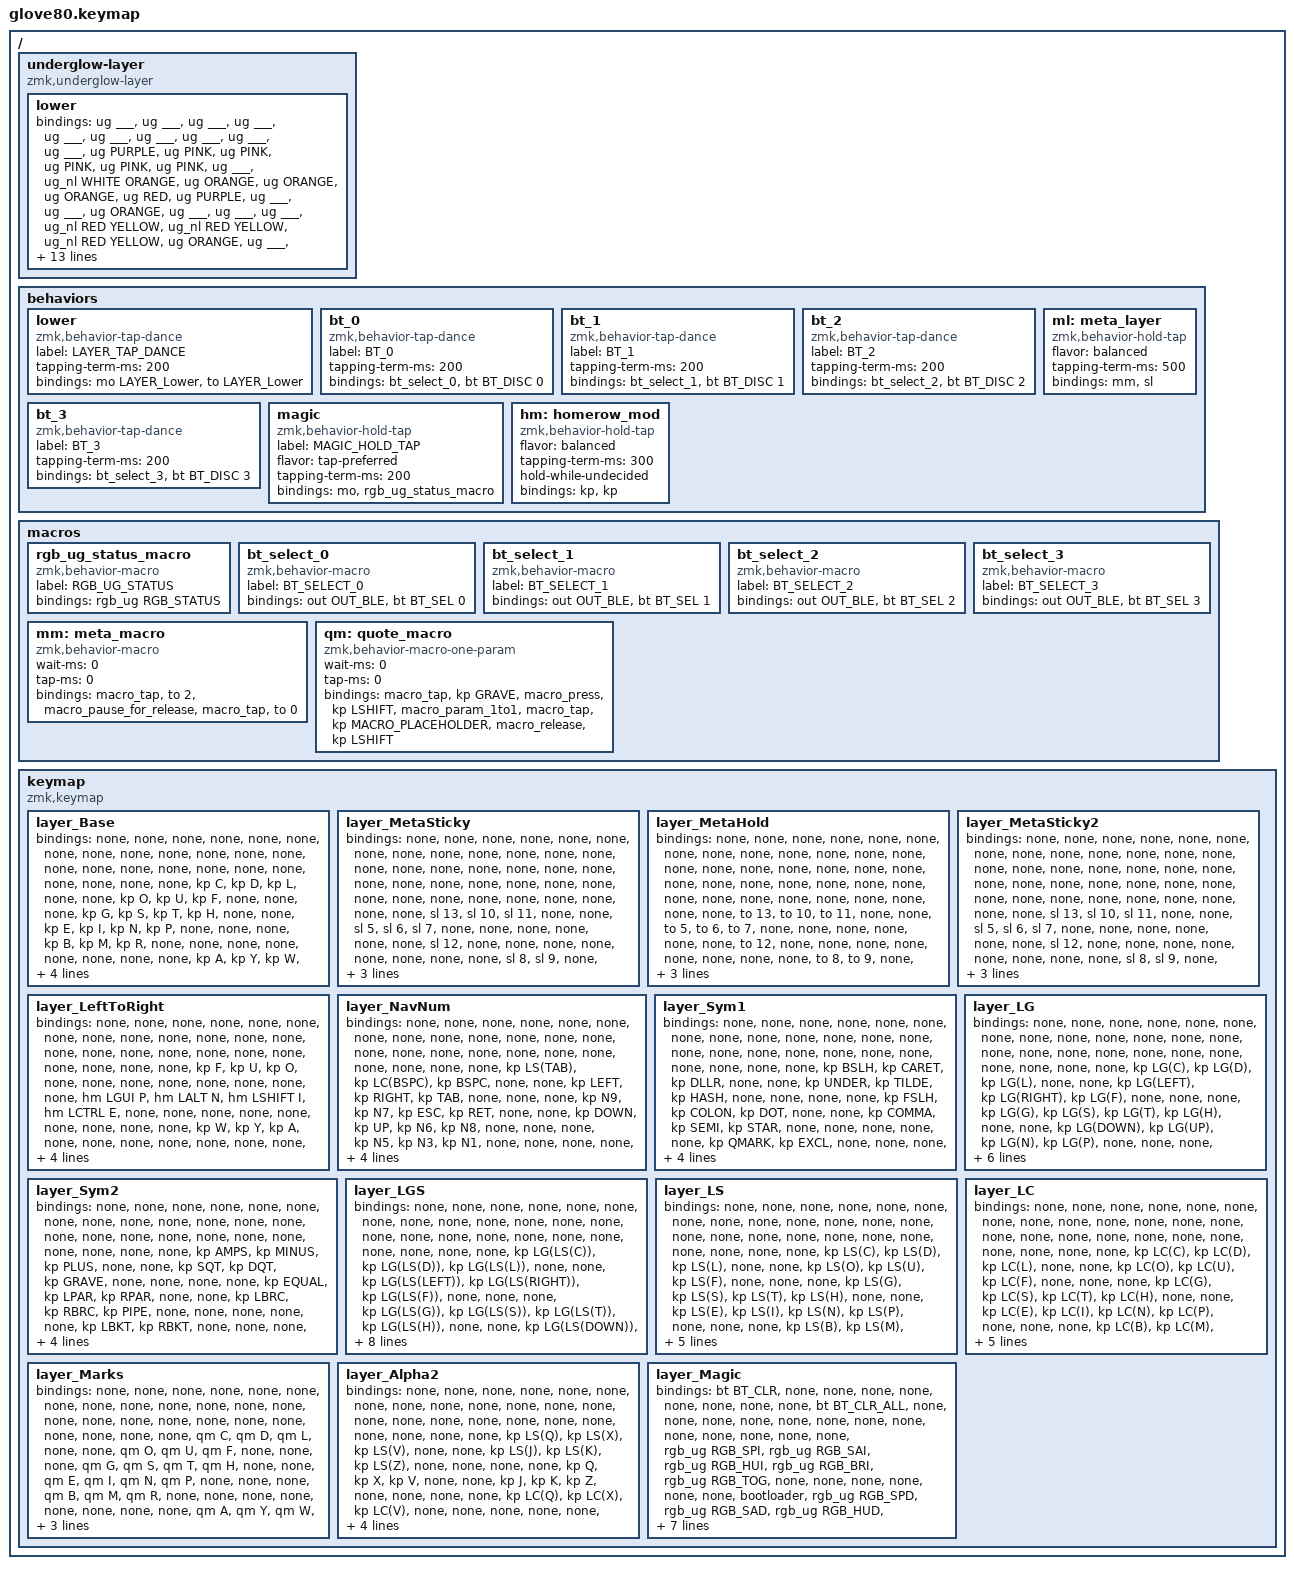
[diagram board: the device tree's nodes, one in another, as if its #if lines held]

/*
 * Copyright (c) 2020 The ZMK Contributors
 * Copyright (c) 2023 Innaworks Development Limited, trading as MoErgo
 *
 * SPDX-License-Identifier: MIT
 */


/* THIS FILE WAS GENERATED BY GLOVE80 LAYOUT EDITOR
 *
 * This file was generated automatically. You may or may not want to
 * edit it directly.
 */

#include <behaviors.dtsi>
/* Include all behavior includes needed */
#include <dt-bindings/zmk/outputs.h>
#include <dt-bindings/zmk/keys.h>
#include <dt-bindings/zmk/bt.h>
#include <dt-bindings/zmk/rgb.h>

/* Automatically generated layer name #define */
#define LAYER_Base 0
#define LAYER_MetaSticky 1
#define LAYER_MetaHold 2
#define LAYER_MetaSticky2 3
#define LAYER_LeftToRight 4
#define LAYER_NavNum 5
#define LAYER_Sym1 6
#define LAYER_Sym2 7
#define LAYER_LG 8
#define LAYER_LGS 9
#define LAYER_LS 10
#define LAYER_LC 11
#define LAYER_Marks 12
#define LAYER_Alpha2 13
#define LAYER_Magic 14

/* To deal with the situation where there is no Lower layer, to keep &lower happy */
#ifndef LAYER_Lower
#define LAYER_Lower 0
#endif

/* Custom Device-tree */
#define GREEN 0x00ff00
#define RED 0xff0000
#define BLUE 0x0000ff
#define TEAL 0x008080
#define ORANGE 0xffa500
#define YELLOW 0xffff00
#define GOLD 0xffd700
#define PURPLE 0x800080
#define PINK 0xffc0cb
#define WHITE 0xffffff
#define ___ 0x000000
/ {
    underglow-layer {
        compatible  = "zmk,underglow-layer";

        lower {
            bindings = <
    &ug ___    &ug ___  &ug ___    &ug ___    &ug ___                                                                                 &ug ___             &ug ___           &ug ___           &ug ___     &ug ___
    &ug PURPLE &ug PINK &ug PINK   &ug   PINK &ug   PINK &ug PINK                                                             &ug ___ &ug_nl WHITE ORANGE &ug ORANGE        &ug ORANGE        &ug ORANGE  &ug RED
    &ug PURPLE &ug ___  &ug ___    &ug ORANGE &ug ___    &ug ___                                                              &ug ___ &ug_nl RED YELLOW   &ug_nl RED YELLOW &ug_nl RED YELLOW &ug ORANGE  &ug ___
    &ug PURPLE &ug ___  &ug ORANGE &ug    RED &ug ORANGE &ug ___                                                              &ug ___ &ug_nl RED YELLOW   &ug_nl RED YELLOW &ug_nl RED YELLOW &ug ORANGE  &ug ___
    &ug   BLUE &ug ___  &ug RED    &ug    RED &ug    RED &ug ___  &ug_cl BLUE TEAL &ug ___   &ug ___  &ug ___ &ug ___ &ug ___ &ug ___ &ug_nl RED YELLOW   &ug_nl RED YELLOW &ug_nl RED YELLOW &ug    RED  &ug BLUE
    &ug ___    &ug ___  &ug ORANGE &ug ORANGE &ug ORANGE          &ug ___          &ug GREEN &ug ___  &ug ___ &ug ___ &ug ___         &ug_nl RED YELLOW   &ug_nl RED YELLOW &ug ORANGE        &ug    RED  &ug ___
                >;
            layer-id = <LAYER_Base>;
        };
    };
};


/* Glove80 system behavior & macros */
/ {
    behaviors {
        // For the "layer" key, it'd nice to be able to use it as either a shift or a toggle.
        // Configure it as a tap dance, so the first tap (or hold) is a &mo and the second tap is a &to
        lower: lower {
            compatible = "zmk,behavior-tap-dance";
            label = "LAYER_TAP_DANCE";
            #binding-cells = <0>;
            tapping-term-ms = <200>;
            bindings = <&mo LAYER_Lower>, <&to LAYER_Lower>;
        };
    };
};

/ {
    macros {
        rgb_ug_status_macro: rgb_ug_status_macro {
            label = "RGB_UG_STATUS";
            compatible = "zmk,behavior-macro";
            #binding-cells = <0>;
            bindings
                = <&rgb_ug RGB_STATUS>;
        };
    };
};


/ {
#ifdef BT_DISC_CMD
    behaviors {
        bt_0: bt_0 {
            compatible = "zmk,behavior-tap-dance";
            label = "BT_0";
            #binding-cells = <0>;
            tapping-term-ms = <200>;
            bindings = <&bt_select_0>, <&bt BT_DISC 0>;
        };
        bt_1: bt_1 {
            compatible = "zmk,behavior-tap-dance";
            label = "BT_1";
            #binding-cells = <0>;
            tapping-term-ms = <200>;
            bindings = <&bt_select_1>, <&bt BT_DISC 1>;
        };
        bt_2: bt_2 {
            compatible = "zmk,behavior-tap-dance";
            label = "BT_2";
            #binding-cells = <0>;
            tapping-term-ms = <200>;
            bindings = <&bt_select_2>, <&bt BT_DISC 2>;
        };
        bt_3: bt_3 {
            compatible = "zmk,behavior-tap-dance";
            label = "BT_3";
            #binding-cells = <0>;
            tapping-term-ms = <200>;
            bindings = <&bt_select_3>, <&bt BT_DISC 3>;
        };
    };
    macros {
        bt_select_0: bt_select_0 {
            label = "BT_SELECT_0";
            compatible = "zmk,behavior-macro";
            #binding-cells = <0>;
            bindings
                = <&out OUT_BLE>,
                  <&bt BT_SEL 0>;
        };
        bt_select_1: bt_select_1 {
            label = "BT_SELECT_1";
            compatible = "zmk,behavior-macro";
            #binding-cells = <0>;
            bindings
                = <&out OUT_BLE>,
                  <&bt BT_SEL 1>;
        };
        bt_select_2: bt_select_2 {
            label = "BT_SELECT_2";
            compatible = "zmk,behavior-macro";
            #binding-cells = <0>;
            bindings
                = <&out OUT_BLE>,
                  <&bt BT_SEL 2>;
        };
        bt_select_3: bt_select_3 {
            label = "BT_SELECT_3";
            compatible = "zmk,behavior-macro";
            #binding-cells = <0>;
            bindings
                = <&out OUT_BLE>,
                  <&bt BT_SEL 3>;
        };
    };
#else
    macros {
        bt_0: bt_0 {
            label = "BT_0";
            compatible = "zmk,behavior-macro";
            #binding-cells = <0>;
            bindings
                = <&out OUT_BLE>,
                  <&bt BT_SEL 0>;
        };
        bt_1: bt_1 {
            label = "BT_1";
            compatible = "zmk,behavior-macro";
            #binding-cells = <0>;
            bindings
                = <&out OUT_BLE>,
                  <&bt BT_SEL 1>;
        };
        bt_2: bt_2 {
            label = "BT_2";
            compatible = "zmk,behavior-macro";
            #binding-cells = <0>;
            bindings
                = <&out OUT_BLE>,
                  <&bt BT_SEL 2>;
        };
        bt_3: bt_3 {
            label = "BT_3";
            compatible = "zmk,behavior-macro";
            #binding-cells = <0>;
            bindings
                = <&out OUT_BLE>,
                  <&bt BT_SEL 3>;
        };
    };
#endif
};

/ {
    behaviors {
        magic: magic {
            compatible = "zmk,behavior-hold-tap";
            label = "MAGIC_HOLD_TAP";
            #binding-cells = <2>;
            flavor = "tap-preferred";
            tapping-term-ms = <200>;
            bindings = <&mo>, <&rgb_ug_status_macro>;
        };
    };
};

/* #define for key positions */
#define POS_LH_T1 52
#define POS_LH_T2 53
#define POS_LH_T3 54
#define POS_LH_T4 69
#define POS_LH_T5 70
#define POS_LH_T6 71
#define POS_LH_C1R2 15
#define POS_LH_C1R3 27
#define POS_LH_C1R4 39
#define POS_LH_C1R5 51
#define POS_LH_C2R1 4
#define POS_LH_C2R2 14
#define POS_LH_C2R3 26
#define POS_LH_C2R4 38
#define POS_LH_C2R5 50
#define POS_LH_C2R6 68
#define POS_LH_C3R1 3
#define POS_LH_C3R2 13
#define POS_LH_C3R3 25
#define POS_LH_C3R4 37
#define POS_LH_C3R5 49
#define POS_LH_C3R6 67
#define POS_LH_C4R1 2
#define POS_LH_C4R2 12
#define POS_LH_C4R3 24
#define POS_LH_C4R4 36
#define POS_LH_C4R5 48
#define POS_LH_C4R6 66
#define POS_LH_C5R1 1
#define POS_LH_C5R2 11
#define POS_LH_C5R3 23
#define POS_LH_C5R4 35
#define POS_LH_C5R5 47
#define POS_LH_C5R6 65
#define POS_LH_C6R1 0
#define POS_LH_C6R2 10
#define POS_LH_C6R3 22
#define POS_LH_C6R4 34
#define POS_LH_C6R5 46
#define POS_LH_C6R6 64
#define POS_RH_T1 57
#define POS_RH_T2 56
#define POS_RH_T3 55
#define POS_RH_T4 74
#define POS_RH_T5 73
#define POS_RH_T6 72
#define POS_RH_C1R2 16
#define POS_RH_C1R3 28
#define POS_RH_C1R4 40
#define POS_RH_C1R5 58
#define POS_RH_C2R1 5
#define POS_RH_C2R2 17
#define POS_RH_C2R3 29
#define POS_RH_C2R4 41
#define POS_RH_C2R5 59
#define POS_RH_C2R6 75
#define POS_RH_C3R1 6
#define POS_RH_C3R2 18
#define POS_RH_C3R3 30
#define POS_RH_C3R4 42
#define POS_RH_C3R5 60
#define POS_RH_C3R6 76
#define POS_RH_C4R1 7
#define POS_RH_C4R2 19
#define POS_RH_C4R3 31
#define POS_RH_C4R4 43
#define POS_RH_C4R5 61
#define POS_RH_C4R6 77
#define POS_RH_C5R1 8
#define POS_RH_C5R2 20
#define POS_RH_C5R3 32
#define POS_RH_C5R4 44
#define POS_RH_C5R5 62
#define POS_RH_C5R6 78
#define POS_RH_C6R1 9
#define POS_RH_C6R2 21
#define POS_RH_C6R3 33
#define POS_RH_C6R4 45
#define POS_RH_C6R5 63
#define POS_RH_C6R6 79

/* Custom Defined Behaviors */
/ {
    behaviors {
        ml: meta_layer {
            compatible = "zmk,behavior-hold-tap";
            flavor = "balanced";
            tapping-term-ms = <500>;
            #binding-cells = <2>;
            bindings = <&mm>, <&sl>;
        };
        hm: homerow_mod {
            compatible = "zmk,behavior-hold-tap";
            flavor = "balanced";
            tapping-term-ms = <300>;
            hold-while-undecided;
            #binding-cells = <2>;
            bindings = <&kp>, <&kp>;
        };
    };

    macros {
        mm: meta_macro {
            compatible = "zmk,behavior-macro";
            wait-ms = <0>;
            tap-ms = <0>;
            #binding-cells = <0>;
            bindings
                = <&macro_tap &to 2>
                , <&macro_pause_for_release>
                , <&macro_tap &to 0>
                ;
        };

        qm: quote_macro {
            compatible = "zmk,behavior-macro-one-param";
            wait-ms = <0>;
            tap-ms = <0>;
            #binding-cells = <1>;
            bindings
                = <&macro_tap &kp GRAVE>
                , <&macro_press &kp LSHIFT>
                , <&macro_param_1to1>
                , <&macro_tap &kp MACRO_PLACEHOLDER>
                , <&macro_release &kp LSHIFT>
                ;
        };
    };

};

/* Automatically generated macro definitions */
/ {
    macros {

    };
};

/* Automatically generated behavior definitions */
/ {
    behaviors {
    
    };
};

/* Automatically generated combos definitions */


/* Automatically generated keymap */
/ {
    keymap {
        compatible = "zmk,keymap";


        layer_Base {
            bindings = <
                &none   &none   &none   &none   &none                                                                       &none   &none   &none   &none                 &none
                &none   &none   &none   &none   &none   &none                                                       &none   &none   &none   &none   &none                 &none
                &none   &none   &kp C   &kp D   &kp L   &none                                                       &none   &kp O   &kp U   &kp F   &none                 &none
                &none   &kp G   &kp S   &kp T   &kp H   &none                                                       &none   &kp E   &kp I   &kp N   &kp P                 &none
                &none   &none   &kp B   &kp M   &kp R   &none      &none   &none   &none   &none   &none    &none   &none   &kp A   &kp Y   &kp W   &none                 &none
 &magic LAYER_Magic 0   &none   &none   &none   &none          &kp SPACE   &sl 4   &none   &none   &none  &ml 1 1           &none   &none   &none   &none  &magic LAYER_Magic 0
            >;
        };

        layer_MetaSticky {
            bindings = <
  &none   &none   &none   &none   &none                                                                   &none   &none   &none   &none   &none
  &none   &none   &none   &none   &none   &none                                                   &none   &none   &none   &none   &none   &none
  &none   &none   &none   &none   &none   &none                                                   &none   &none   &none   &none   &none   &none
  &none   &none  &sl 13  &sl 10  &sl 11   &none                                                   &none   &sl 5   &sl 6   &sl 7   &none   &none
  &none   &none   &none   &none  &sl 12   &none   &none   &none   &none   &none   &none   &none   &none   &sl 8   &sl 9   &none   &none   &none
  &none   &none   &none   &none   &none           &mo 3   &none   &none   &none   &none   &none           &none   &none   &none   &none   &none
            >;
        };

        layer_MetaHold {
            bindings = <
  &none   &none   &none   &none   &none                                                                   &none   &none   &none   &none   &none
  &none   &none   &none   &none   &none   &none                                                   &none   &none   &none   &none   &none   &none
  &none   &none   &none   &none   &none   &none                                                   &none   &none   &none   &none   &none   &none
  &none   &none  &to 13  &to 10  &to 11   &none                                                   &none   &to 5   &to 6   &to 7   &none   &none
  &none   &none   &none   &none  &to 12   &none   &none   &none   &none   &none   &none   &none   &none   &to 8   &to 9   &none   &none   &none
  &none   &none   &none   &none   &none           &none   &none   &none   &none   &none   &none           &none   &none   &none   &none   &none
            >;
        };

        layer_MetaSticky2 {
            bindings = <
  &none   &none   &none   &none   &none                                                                   &none   &none   &none   &none   &none
  &none   &none   &none   &none   &none   &none                                                   &none   &none   &none   &none   &none   &none
  &none   &none   &none   &none   &none   &none                                                   &none   &none   &none   &none   &none   &none
  &none   &none  &sl 13  &sl 10  &sl 11   &none                                                   &none   &sl 5   &sl 6   &sl 7   &none   &none
  &none   &none   &none   &none  &sl 12   &none   &none   &none   &none   &none   &none   &none   &none   &sl 8   &sl 9   &none   &none   &none
  &none   &none   &none   &none   &none           &none   &none   &none   &none   &none   &none           &none   &none   &none   &none   &none
            >;
        };

        layer_LeftToRight {
            bindings = <
  &none       &none       &none         &none        &none                                                                    &none   &none   &none   &none   &none
  &none       &none       &none         &none        &none   &none                                                    &none   &none   &none   &none   &none   &none
  &none       &none       &kp F         &kp U        &kp O   &none                                                    &none   &none   &none   &none   &none   &none
  &none  &hm LGUI P  &hm LALT N  &hm LSHIFT I  &hm LCTRL E   &none                                                    &none   &none   &none   &none   &none   &none
  &none       &none       &kp W         &kp Y        &kp A   &none   &none    &none   &none   &none   &none   &none   &none   &none   &none   &none   &none   &none
  &none       &none       &none         &none        &none           &none  &kp ESC   &none   &none   &none   &none           &none   &none   &none   &none   &none
            >;
        };

        layer_NavNum {
            bindings = <
  &none   &none        &none         &none     &none                                                                     &none      &none    &none   &none   &none
  &none   &none        &none         &none     &none   &none                                                   &none     &none      &none    &none   &none   &none
  &none   &none  &kp LS(TAB)  &kp LC(BSPC)  &kp BSPC   &none                                                   &none  &kp LEFT  &kp RIGHT  &kp TAB   &none   &none
  &none  &kp N9       &kp N7       &kp ESC   &kp RET   &none                                                   &none  &kp DOWN     &kp UP   &kp N6  &kp N8   &none
  &none   &none       &kp N5        &kp N3    &kp N1   &none   &none   &none   &none   &none   &none   &none   &none    &kp N0     &kp N2   &kp N4   &none   &none
  &none   &none        &none         &none     &none           &none   &none   &none   &none   &none   &none             &none      &none    &none   &none   &none
            >;
        };

        layer_Sym1 {
            bindings = <
  &none   &none     &none      &none     &none                                                                      &none      &none     &none   &none   &none
  &none   &none     &none      &none     &none   &none                                                   &none      &none      &none     &none   &none   &none
  &none   &none  &kp BSLH  &kp CARET  &kp DLLR   &none                                                   &none  &kp UNDER  &kp TILDE  &kp HASH   &none   &none
  &none   &none  &kp FSLH  &kp COLON   &kp DOT   &none                                                   &none  &kp COMMA   &kp SEMI  &kp STAR   &none   &none
  &none   &none     &none  &kp QMARK  &kp EXCL   &none   &none   &none   &none   &none   &none   &none   &none  &kp PRCNT     &kp AT     &none   &none   &none
  &none   &none     &none      &none     &none           &none   &none   &none   &none   &none   &none              &none      &none     &none   &none   &none
            >;
        };

        layer_Sym2 {
            bindings = <
  &none   &none      &none      &none     &none                                                                     &none     &none      &none   &none   &none
  &none   &none      &none      &none     &none   &none                                                   &none     &none     &none      &none   &none   &none
  &none   &none   &kp AMPS  &kp MINUS  &kp PLUS   &none                                                   &none   &kp SQT   &kp DQT  &kp GRAVE   &none   &none
  &none   &none  &kp EQUAL   &kp LPAR  &kp RPAR   &none                                                   &none  &kp LBRC  &kp RBRC   &kp PIPE   &none   &none
  &none   &none      &none   &kp LBKT  &kp RBKT   &none   &none   &none   &none   &none   &none   &none   &none    &kp LT    &kp GT      &none   &none   &none
  &none   &none      &none      &none     &none           &none   &none   &none   &none   &none   &none             &none     &none      &none   &none   &none
            >;
        };

        layer_LG {
            bindings = <
  &none      &none      &none      &none      &none                                                                         &none          &none      &none      &none   &none
  &none      &none      &none      &none      &none   &none                                                   &none         &none          &none      &none      &none   &none
  &none      &none  &kp LG(C)  &kp LG(D)  &kp LG(L)   &none                                                   &none  &kp LG(LEFT)  &kp LG(RIGHT)  &kp LG(F)      &none   &none
  &none  &kp LG(G)  &kp LG(S)  &kp LG(T)  &kp LG(H)   &none                                                   &none  &kp LG(DOWN)     &kp LG(UP)  &kp LG(N)  &kp LG(P)   &none
  &none      &none  &kp LG(B)  &kp LG(M)  &kp LG(R)   &none   &none   &none   &none   &none   &none   &none   &none     &kp LG(A)      &kp LG(Y)  &kp LG(W)      &none   &none
  &none      &none      &none      &none      &none           &none   &none   &none   &none   &none   &none                 &none          &none      &none      &none   &none
            >;
        };

        layer_LGS {
            bindings = <
  &none          &none          &none          &none          &none                                                                             &none              &none          &none          &none   &none
  &none          &none          &none          &none          &none   &none                                                   &none             &none              &none          &none          &none   &none
  &none          &none  &kp LG(LS(C))  &kp LG(LS(D))  &kp LG(LS(L))   &none                                                   &none  &kp LG(LS(LEFT))  &kp LG(LS(RIGHT))  &kp LG(LS(F))          &none   &none
  &none  &kp LG(LS(G))  &kp LG(LS(S))  &kp LG(LS(T))  &kp LG(LS(H))   &none                                                   &none  &kp LG(LS(DOWN))     &kp LG(LS(UP))  &kp LG(LS(N))  &kp LG(LS(P))   &none
  &none          &none  &kp LG(LS(B))  &kp LG(LS(M))  &kp LG(LS(R))   &none   &none   &none   &none   &none   &none   &none   &none     &kp LG(LS(A))      &kp LG(LS(Y))  &kp LG(LS(W))          &none   &none
  &none          &none          &none          &none          &none           &none   &none   &none   &none   &none   &none                     &none              &none          &none          &none   &none
            >;
        };

        layer_LS {
            bindings = <
  &none      &none      &none      &none      &none                                                                      &none      &none      &none      &none   &none
  &none      &none      &none      &none      &none   &none                                                   &none      &none      &none      &none      &none   &none
  &none      &none  &kp LS(C)  &kp LS(D)  &kp LS(L)   &none                                                   &none  &kp LS(O)  &kp LS(U)  &kp LS(F)      &none   &none
  &none  &kp LS(G)  &kp LS(S)  &kp LS(T)  &kp LS(H)   &none                                                   &none  &kp LS(E)  &kp LS(I)  &kp LS(N)  &kp LS(P)   &none
  &none      &none  &kp LS(B)  &kp LS(M)  &kp LS(R)   &none   &none   &none   &none   &none   &none   &none   &none  &kp LS(A)  &kp LS(Y)  &kp LS(W)      &none   &none
  &none      &none      &none      &none      &none           &none   &none   &none   &none   &none   &none              &none      &none      &none      &none   &none
            >;
        };

        layer_LC {
            bindings = <
  &none      &none      &none      &none      &none                                                                      &none      &none      &none      &none   &none
  &none      &none      &none      &none      &none   &none                                                   &none      &none      &none      &none      &none   &none
  &none      &none  &kp LC(C)  &kp LC(D)  &kp LC(L)   &none                                                   &none  &kp LC(O)  &kp LC(U)  &kp LC(F)      &none   &none
  &none  &kp LC(G)  &kp LC(S)  &kp LC(T)  &kp LC(H)   &none                                                   &none  &kp LC(E)  &kp LC(I)  &kp LC(N)  &kp LC(P)   &none
  &none      &none  &kp LC(B)  &kp LC(M)  &kp LC(R)   &none   &none   &none   &none   &none   &none   &none   &none  &kp LC(A)  &kp LC(Y)  &kp LC(W)      &none   &none
  &none      &none      &none      &none      &none           &none   &none   &none   &none   &none   &none              &none      &none      &none      &none   &none
            >;
        };

        layer_Marks {
            bindings = <
  &none   &none   &none   &none   &none                                                                   &none   &none   &none   &none   &none
  &none   &none   &none   &none   &none   &none                                                   &none   &none   &none   &none   &none   &none
  &none   &none   &qm C   &qm D   &qm L   &none                                                   &none   &qm O   &qm U   &qm F   &none   &none
  &none   &qm G   &qm S   &qm T   &qm H   &none                                                   &none   &qm E   &qm I   &qm N   &qm P   &none
  &none   &none   &qm B   &qm M   &qm R   &none   &none   &none   &none   &none   &none   &none   &none   &qm A   &qm Y   &qm W   &none   &none
  &none   &none   &none   &none   &none           &none   &none   &none   &none   &none   &none           &none   &none   &none   &none   &none
            >;
        };

        layer_Alpha2 {
            bindings = <
  &none   &none      &none      &none      &none                                                                      &none      &none      &none   &none   &none
  &none   &none      &none      &none      &none   &none                                                   &none      &none      &none      &none   &none   &none
  &none   &none  &kp LS(Q)  &kp LS(X)  &kp LS(V)   &none                                                   &none  &kp LS(J)  &kp LS(K)  &kp LS(Z)   &none   &none
  &none   &none      &kp Q      &kp X      &kp V   &none                                                   &none      &kp J      &kp K      &kp Z   &none   &none
  &none   &none  &kp LC(Q)  &kp LC(X)  &kp LC(V)   &none   &none   &none   &none   &none   &none   &none   &none  &kp LC(J)  &kp LC(K)  &kp LC(Z)   &none   &none
  &none   &none      &none      &none      &none           &none   &none   &none   &none   &none   &none              &none      &none      &none   &none   &none
            >;
        };

        layer_Magic {
            bindings = <
  &bt BT_CLR            &none            &none            &none            &none                                                                                  &none   &none   &none   &none  &bt BT_CLR_ALL
       &none            &none            &none            &none            &none            &none                                                         &none   &none   &none   &none   &none           &none
       &none  &rgb_ug RGB_SPI  &rgb_ug RGB_SAI  &rgb_ug RGB_HUI  &rgb_ug RGB_BRI  &rgb_ug RGB_TOG                                                         &none   &none   &none   &none   &none           &none
 &bootloader  &rgb_ug RGB_SPD  &rgb_ug RGB_SAD  &rgb_ug RGB_HUD  &rgb_ug RGB_BRD  &rgb_ug RGB_EFF                                                         &none   &none   &none   &none   &none     &bootloader
  &sys_reset            &none            &none            &none            &none            &none   &bt_2   &bt_3         &none   &none   &none   &none   &none   &none   &none   &none   &none      &sys_reset
       &none            &none            &none            &none            &none                    &bt_0   &bt_1  &out OUT_USB   &none   &none   &none           &none   &none   &none   &none           &none
            >;
        };

    };
};
